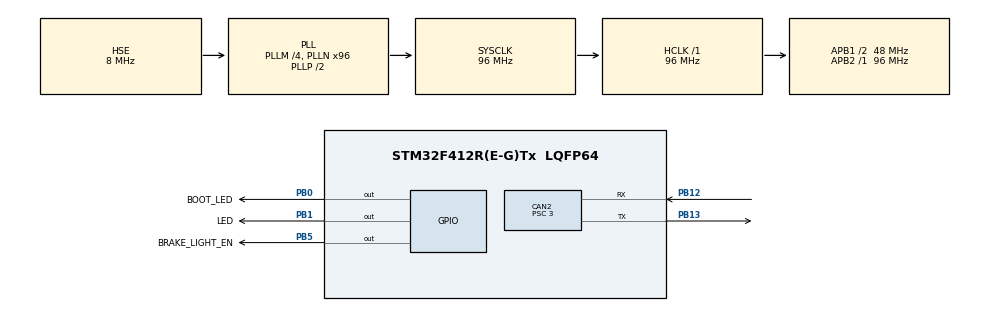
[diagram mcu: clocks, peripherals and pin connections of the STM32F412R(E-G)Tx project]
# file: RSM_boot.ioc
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CAN2.ABOM=ENABLE
CAN2.BS1=CAN_BS1_12TQ
CAN2.BS2=CAN_BS2_3TQ
CAN2.CalculateBaudRate=1000000
CAN2.CalculateTimeBit=1000
CAN2.CalculateTimeQuantum=62.5
CAN2.NART=ENABLE
CAN2.Prescaler=3
CAN2.RFLM=ENABLE
CAN2.SJW=CAN_SJW_3TQ
CAN2.TXFP=ENABLE
FREERTOS.Tasks01=interfaceTask,48,512,runInterfaceTask,Default,NULL,Static,interfaceTaskBuffer,interfaceTaskControlBlock;canTxTask,40,512,runCanTxTask,Default,NULL,Static,canTxTaskBuffer,canTxTaskControlBlock;tickTask,8,512,runTickTask,Default,NULL,Static,tickTaskBuffer,tickTaskControlBlock
Mcu.Family=STM32F4
Mcu.Name=STM32F412R(E-G)Tx
Mcu.Package=LQFP64
NVIC.CAN2_RX0_IRQn=true\:5\:0\:false\:false\:true\:true\:true\:true\:true
NVIC.CAN2_RX1_IRQn=true\:5\:0\:false\:false\:true\:true\:true\:true\:true
NVIC.CAN2_SCE_IRQn=true\:5\:0\:false\:false\:true\:true\:true\:true\:true
NVIC.CAN2_TX_IRQn=true\:5\:0\:false\:false\:true\:true\:true\:true\:true
NVIC.PriorityGroup=NVIC_PRIORITYGROUP_4
NVIC.TIM6_IRQn=true\:15\:0\:false\:false\:true\:false\:false\:true\:true
NVIC.TimeBase=TIM6_IRQn
NVIC.TimeBaseIP=TIM6
PA13.GPIO_Label=SWDIO
PA13.Mode=Trace_Asynchronous_SW
PA13.Signal=SYS_JTMS-SWDIO
PA14.GPIO_Label=SWCLK
PA14.Mode=Trace_Asynchronous_SW
PA14.Signal=SYS_JTCK-SWCLK
PB0.GPIO_Label=BOOT_LED
PB0.PinState=GPIO_PIN_SET
PB0.Signal=GPIO_Output
PB1.GPIO_Label=LED
PB1.Signal=GPIO_Output
PB12.Mode=CAN_Activate
PB12.Signal=CAN2_RX
PB13.Mode=CAN_Activate
PB13.Signal=CAN2_TX
PB3.GPIO_Label=SWO
PB3.Mode=Trace_Asynchronous_SW
PB3.Signal=SYS_JTDO-SWO
PB5.GPIO_Label=BRAKE_LIGHT_EN
PB5.Signal=GPIO_Output
PH0\ -\ OSC_IN.Mode=HSE-External-Oscillator
PH0\ -\ OSC_IN.Signal=RCC_OSC_IN
PH1\ -\ OSC_OUT.Mode=HSE-External-Oscillator
PH1\ -\ OSC_OUT.Signal=RCC_OSC_OUT
ProjectManager.HeapSize=0x200
ProjectManager.StackSize=0x400
ProjectManager.TargetToolchain=STM32CubeIDE
RCC.AHBFreq_Value=96000000
RCC.APB1CLKDivider=RCC_HCLK_DIV2
RCC.APB1Freq_Value=48000000
RCC.APB1TimFreq_Value=96000000
RCC.APB2Freq_Value=96000000
RCC.APB2TimFreq_Value=96000000
RCC.CortexFreq_Value=96000000
RCC.HCLKFreq_Value=96000000
RCC.HSE_VALUE=8000000
RCC.PLLM=4
RCC.PLLN=96
RCC.PLLQ=4
RCC.PLLSourceVirtual=RCC_PLLSOURCE_HSE
RCC.SYSCLKFreq_VALUE=96000000
RCC.SYSCLKSource=RCC_SYSCLKSOURCE_PLLCLK
RCC.USBFreq_Value=48000000
RCC.VCOOutputFreq_Value=192000000
VP_FREERTOS_VS_CMSIS_V2.Mode=CMSIS_V2
VP_SYS_VS_tim6.Mode=TIM6
board=custom

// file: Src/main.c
/* USER CODE BEGIN Header */
/**
 ******************************************************************************
 * @file           : main.c
 * @brief          : Main program body
 ******************************************************************************
 * @attention
 *
 * Copyright (c) 2024 STMicroelectronics.
 * All rights reserved.
 *
 * This software is licensed under terms that can be found in the LICENSE file
 * in the root directory of this software component.
 * If no LICENSE file comes with this software, it is provided AS-IS.
 *
 ******************************************************************************
 */
/* USER CODE END Header */
#include "main.h"
#include "cmsis_os.h"

/* USER CODE BEGIN Includes */
#include "bootloader.h"
#include "hw/can.h"
#include "io/canQueue.h"
#include "hw/error.h"
/* USER CODE END Includes */

typedef StaticTask_t osStaticThreadDef_t;

CAN_HandleTypeDef hcan2;

/* Definitions for interfaceTask */
osThreadId_t         interfaceTaskHandle;
uint32_t             interfaceTaskBuffer[512];
osStaticThreadDef_t  interfaceTaskControlBlock;
const osThreadAttr_t interfaceTask_attributes = {
    .name       = "interfaceTask",
    .cb_mem     = &interfaceTaskControlBlock,
    .cb_size    = sizeof(interfaceTaskControlBlock),
    .stack_mem  = &interfaceTaskBuffer[0],
    .stack_size = sizeof(interfaceTaskBuffer),
    .priority   = (osPriority_t)osPriorityRealtime,
};
/* Definitions for canTxTask */
osThreadId_t         canTxTaskHandle;
uint32_t             canTxTaskBuffer[512];
osStaticThreadDef_t  canTxTaskControlBlock;
const osThreadAttr_t canTxTask_attributes = {
    .name       = "canTxTask",
    .cb_mem     = &canTxTaskControlBlock,
    .cb_size    = sizeof(canTxTaskControlBlock),
    .stack_mem  = &canTxTaskBuffer[0],
    .stack_size = sizeof(canTxTaskBuffer),
    .priority   = (osPriority_t)osPriorityHigh,
};
/* Definitions for tickTask */
osThreadId_t         tickTaskHandle;
uint32_t             tickTaskBuffer[512];
osStaticThreadDef_t  tickTaskControlBlock;
const osThreadAttr_t tickTask_attributes = {
    .name       = "tickTask",
    .cb_mem     = &tickTaskControlBlock,
    .cb_size    = sizeof(tickTaskControlBlock),
    .stack_mem  = &tickTaskBuffer[0],
    .stack_size = sizeof(tickTaskBuffer),
    .priority   = (osPriority_t)osPriorityLow,
};
/* USER CODE BEGIN PV */
CanHandle can = { .hcan = &hcan2, .bus_num = 2, .receive_callback = io_canQueue_pushRx };
/* USER CODE END PV */

void        SystemClock_Config(void);
static void MX_GPIO_Init(void);
static void MX_CAN2_Init(void);
void        runInterfaceTask(void *argument);
void        runCanTxTask(void *argument);
void        runTickTask(void *argument);

int main(void)
{
    /* USER CODE BEGIN 1 */
    bootloader_preInit();
    /* USER CODE END 1 */

    /* MCU Configuration--------------------------------------------------------*/

    /* Reset of all peripherals, Initializes the Flash interface and the Systick. */
    HAL_Init();

    /* Configure the system clock */
    SystemClock_Config();

    /* Initialize all configured peripherals */
    MX_GPIO_Init();
    MX_CAN2_Init();
    /* USER CODE BEGIN 2 */
    bootloader_init();
    /* USER CODE END 2 */

    /* Init scheduler */
    osKernelInitialize();

    /* Create the thread(s) */
    /* creation of interfaceTask */
    interfaceTaskHandle = osThreadNew(runInterfaceTask, NULL, &interfaceTask_attributes);

    /* creation of canTxTask */
    canTxTaskHandle = osThreadNew(runCanTxTask, NULL, &canTxTask_attributes);

    /* creation of tickTask */
    tickTaskHandle = osThreadNew(runTickTask, NULL, &tickTask_attributes);

    /* Start scheduler */
    osKernelStart();

    /* We should never get here as control is now taken by the scheduler */

    /* Infinite loop */
    while (1)
    {

    }
}

void SystemClock_Config(void)
{
    RCC_OscInitTypeDef RCC_OscInitStruct = { 0 };
    RCC_ClkInitTypeDef RCC_ClkInitStruct = { 0 };

    /** Configure the main internal regulator output voltage
     */
    __HAL_RCC_PWR_CLK_ENABLE();
    __HAL_PWR_VOLTAGESCALING_CONFIG(PWR_REGULATOR_VOLTAGE_SCALE1);

    /** Initializes the RCC Oscillators according to the specified parameters
     * in the RCC_OscInitTypeDef structure.
     */
    RCC_OscInitStruct.OscillatorType = RCC_OSCILLATORTYPE_HSE;
    RCC_OscInitStruct.HSEState       = RCC_HSE_ON;
    RCC_OscInitStruct.PLL.PLLState   = RCC_PLL_ON;
    RCC_OscInitStruct.PLL.PLLSource  = RCC_PLLSOURCE_HSE;
    RCC_OscInitStruct.PLL.PLLM       = 4;
    RCC_OscInitStruct.PLL.PLLN       = 96;
    RCC_OscInitStruct.PLL.PLLP       = RCC_PLLP_DIV2;
    RCC_OscInitStruct.PLL.PLLQ       = 4;
    RCC_OscInitStruct.PLL.PLLR       = 2;
    if (HAL_RCC_OscConfig(&RCC_OscInitStruct) != HAL_OK)
    {
        Error_Handler();
    }

    /** Initializes the CPU, AHB and APB buses clocks
     */
    RCC_ClkInitStruct.ClockType = RCC_CLOCKTYPE_HCLK | RCC_CLOCKTYPE_SYSCLK | RCC_CLOCKTYPE_PCLK1 | RCC_CLOCKTYPE_PCLK2;
    RCC_ClkInitStruct.SYSCLKSource   = RCC_SYSCLKSOURCE_PLLCLK;
    RCC_ClkInitStruct.AHBCLKDivider  = RCC_SYSCLK_DIV1;
    RCC_ClkInitStruct.APB1CLKDivider = RCC_HCLK_DIV2;
    RCC_ClkInitStruct.APB2CLKDivider = RCC_HCLK_DIV1;

    if (HAL_RCC_ClockConfig(&RCC_ClkInitStruct, FLASH_LATENCY_3) != HAL_OK)
    {
        Error_Handler();
    }
}

static void MX_CAN2_Init(void)
{

    hcan2.Instance                  = CAN2;
    hcan2.Init.Prescaler            = 3;
    hcan2.Init.Mode                 = CAN_MODE_NORMAL;
    hcan2.Init.SyncJumpWidth        = CAN_SJW_3TQ;
    hcan2.Init.TimeSeg1             = CAN_BS1_12TQ;
    hcan2.Init.TimeSeg2             = CAN_BS2_3TQ;
    hcan2.Init.TimeTriggeredMode    = DISABLE;
    hcan2.Init.AutoBusOff           = ENABLE;
    hcan2.Init.AutoWakeUp           = DISABLE;
    hcan2.Init.AutoRetransmission   = ENABLE;
    hcan2.Init.ReceiveFifoLocked    = ENABLE;
    hcan2.Init.TransmitFifoPriority = ENABLE;
    if (HAL_CAN_Init(&hcan2) != HAL_OK)
    {
        Error_Handler();
    }
}

static void MX_GPIO_Init(void)
{
    GPIO_InitTypeDef GPIO_InitStruct = { 0 };

    /* GPIO Ports Clock Enable */
    __HAL_RCC_GPIOH_CLK_ENABLE();
    __HAL_RCC_GPIOB_CLK_ENABLE();
    __HAL_RCC_GPIOA_CLK_ENABLE();

    /*Configure GPIO pin Output Level */
    HAL_GPIO_WritePin(BOOT_LED_GPIO_Port, BOOT_LED_Pin, GPIO_PIN_SET);

    /*Configure GPIO pin Output Level */
    HAL_GPIO_WritePin(GPIOB, LED_Pin | BRAKE_LIGHT_EN_Pin, GPIO_PIN_RESET);

    /*Configure GPIO pins : BOOT_LED_Pin LED_Pin BRAKE_LIGHT_EN_Pin */
    GPIO_InitStruct.Pin   = BOOT_LED_Pin | LED_Pin | BRAKE_LIGHT_EN_Pin;
    GPIO_InitStruct.Mode  = GPIO_MODE_OUTPUT_PP;
    GPIO_InitStruct.Pull  = GPIO_NOPULL;
    GPIO_InitStruct.Speed = GPIO_SPEED_FREQ_LOW;
    HAL_GPIO_Init(GPIOB, &GPIO_InitStruct);

}

void runInterfaceTask(void *argument)
{
    /* USER CODE BEGIN 5 */
    bootloader_runInterfaceTask();
    /* USER CODE END 5 */
}

void runCanTxTask(void *argument)
{
    /* USER CODE BEGIN runCanTxTask */
    /* Infinite loop */
    bootloader_runCanTxTask();
    /* USER CODE END runCanTxTask */
}

void runTickTask(void *argument)
{
    /* USER CODE BEGIN runTickTask */
    /* Infinite loop */
    bootloader_runTickTask();
    /* USER CODE END runTickTask */
}

void HAL_TIM_PeriodElapsedCallback(TIM_HandleTypeDef *htim)
{
    if (htim->Instance == TIM6)
    {
        HAL_IncTick();
    }
}

void Error_Handler(void)
{
    __disable_irq();
    while (1)
    {
    }
}
